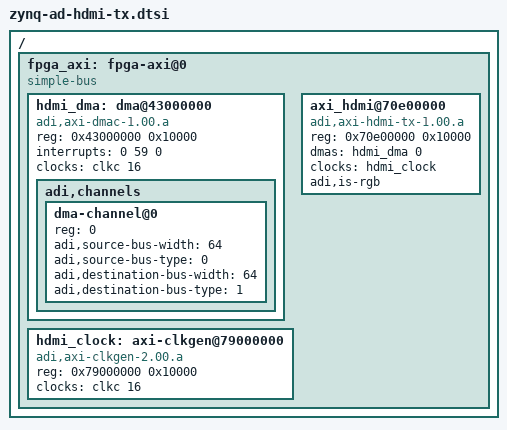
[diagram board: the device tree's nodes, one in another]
/ {
	fpga_axi: fpga-axi@0 {
		compatible = "simple-bus";
		#address-cells = <0x1>;
		#size-cells = <0x1>;
		ranges;
		
		hdmi_dma: dma@43000000 {
			compatible = "adi,axi-dmac-1.00.a";
			reg = <0x43000000 0x10000>;
			#dma-cells = <1>;
			interrupts = <0 59 0>;
			clocks = <&clkc 16>;

			adi,channels {
				#size-cells = <0>;
				#address-cells = <1>;

				dma-channel@0 {
					reg = <0>;
					adi,source-bus-width = <64>;
					adi,source-bus-type = <0>;
					adi,destination-bus-width = <64>;
					adi,destination-bus-type = <1>;
				};
			};
		};

		hdmi_clock: axi-clkgen@79000000 {
			compatible = "adi,axi-clkgen-2.00.a";
			reg = <0x79000000 0x10000>;
			#clock-cells = <0>;
			clocks = <&clkc 16>;
		};

		axi_hdmi@70e00000 {
			compatible = "adi,axi-hdmi-tx-1.00.a";
			reg = <0x70e00000 0x10000>;
			dmas = <&hdmi_dma 0>;
			dma-names = "video";
			clocks = <&hdmi_clock>;
			adi,is-rgb;
		};
	};
};
